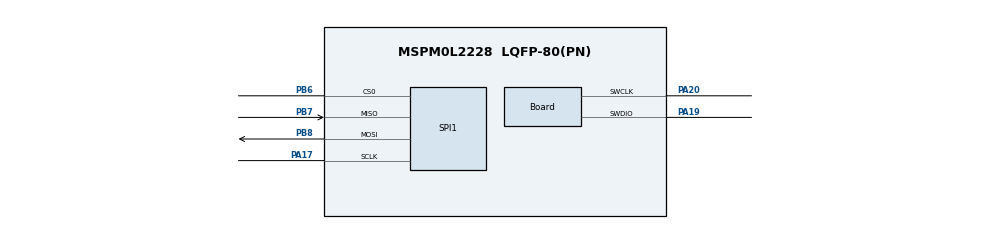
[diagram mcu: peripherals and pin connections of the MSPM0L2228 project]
//@cliArgs --device "MSPM0L222X" --package "LQFP-80(PN)" --part "Default"
//@v2CliArgs --device "MSPM0L2228" --package "LQFP-80(PN)"
// @cliArgs --board /ti/boards/LP_MSPM0L2228 --rtos nortos

/**
 * Import the modules used in this configuration.
 */
const GPIO          = scripting.addModule("/ti/driverlib/GPIO", {}, false);
const GPIO1         = GPIO.addInstance();
const GPIO2         = GPIO.addInstance();
const SPI           = scripting.addModule("/ti/driverlib/SPI", {}, false);
const SPI1          = SPI.addInstance();
const ProjectConfig = scripting.addModule("/ti/project_config/ProjectConfig");

/**
 * Write custom configuration values to the imported modules.
 */
GPIO1.$name                          = "GPIO_LEDS";
GPIO1.associatedPins.create(2);
GPIO1.associatedPins[0].$name        = "USER_LED_1";
GPIO1.associatedPins[0].assignedPort = "PORTA";
GPIO1.associatedPins[0].assignedPin  = "23";
GPIO1.associatedPins[1].$name        = "USER_LED_2";
GPIO1.associatedPins[1].assignedPort = "PORTB";
GPIO1.associatedPins[1].assignedPin  = "9";

const Board                       = scripting.addModule("/ti/driverlib/Board", {}, false);
Board.peripheral.$assign          = "DEBUGSS";
Board.peripheral.swclkPin.$assign = "PA20";
Board.peripheral.swdioPin.$assign = "PA19";

GPIO2.$name                          = "GPIO_SWITCHES";
GPIO2.associatedPins[0].direction    = "INPUT";
GPIO2.associatedPins[0].interruptEn  = true;
GPIO2.associatedPins[0].$name        = "USER_SWITCH_1";
GPIO2.associatedPins[0].assignedPort = "PORTA";
GPIO2.associatedPins[0].assignedPin  = "18";
GPIO2.associatedPins[0].polarity     = "RISE";

SPI1.$name                              = "SPI_0";
SPI1.mode                               = "PERIPHERAL";
SPI1.rxFifoThreshold                    = "DL_SPI_RX_FIFO_LEVEL_ONE_FRAME";
SPI1.enabledInterrupts                  = ["RX"];
SPI1.peripheral.$assign                 = "SPI1";
SPI1.peripheral.sclkPin.$assign         = "PA17";
SPI1.peripheral.mosiPin.$assign         = "PB8";
SPI1.peripheral.misoPin.$assign         = "PB7";
SPI1.peripheral.cs0Pin.$assign          = "PB6";

const SYSCTL              = scripting.addModule("/ti/driverlib/SYSCTL", {}, false);
SYSCTL.peripheral.$assign = "SYSCTL";

ProjectConfig.genLinker          = false;
ProjectConfig.migrationCondition = true;
ProjectConfig.genStartup         = false;
scripting.suppress("All four File Generation options must be enabled in order to guarantee Device Migration support\\. If an option is disabled, the user must manually configure that setting on its own file\\.", ProjectConfig);
